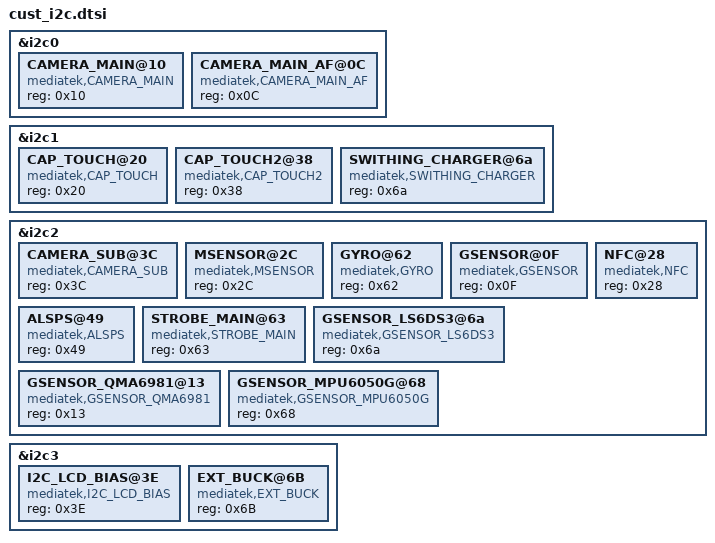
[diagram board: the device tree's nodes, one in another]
/*
 * Generated by MTK SP DrvGen Version 03.13.6 for MT6735M. Copyright MediaTek Inc. (C) 2013.
 * Tue Dec 06 09:41:16 2016
 * Do Not Modify the File.
 */

/*************************
 * I2C DTSI File
*************************/

&i2c0 {
	CAMERA_MAIN@10 {
		compatible = "mediatek,CAMERA_MAIN";
		reg = <0x10>;
	};

	CAMERA_MAIN_AF@0C {
		compatible = "mediatek,CAMERA_MAIN_AF";
		reg = <0x0C>;
	};

};

&i2c1 {
	CAP_TOUCH@20 {
		compatible = "mediatek,CAP_TOUCH";
		reg = <0x20>;
	};

	CAP_TOUCH2@38 {
		compatible = "mediatek,CAP_TOUCH2";
		reg = <0x38>;
	};

	SWITHING_CHARGER@6a {
		compatible = "mediatek,SWITHING_CHARGER";
		reg = <0x6a>;
	};

};

&i2c2 {
	CAMERA_SUB@3C {
		compatible = "mediatek,CAMERA_SUB";
		reg = <0x3C>;
	};

	MSENSOR@2C {
		compatible = "mediatek,MSENSOR";
		reg = <0x2C>;
	};

	GYRO@62 {
		compatible = "mediatek,GYRO";
		reg = <0x62>;
	};

	GSENSOR@0F {
		compatible = "mediatek,GSENSOR";
		reg = <0x0F>;
	};

	ALSPS@49 {
		compatible = "mediatek,ALSPS";
		reg = <0x49>;
	};

	NFC@28 {
		compatible = "mediatek,NFC";
		reg = <0x28>;
	};

	STROBE_MAIN@63 {
		compatible = "mediatek,STROBE_MAIN";
		reg = <0x63>;
	};

	GSENSOR_LS6DS3@6a {
		compatible = "mediatek,GSENSOR_LS6DS3";
		reg = <0x6a>;
	};

	GSENSOR_QMA6981@13 {
		compatible = "mediatek,GSENSOR_QMA6981";
		reg = <0x13>;
	};

	GSENSOR_MPU6050G@68 {
		compatible = "mediatek,GSENSOR_MPU6050G";
		reg = <0x68>;
	};

};

&i2c3 {
	I2C_LCD_BIAS@3E {
		compatible = "mediatek,I2C_LCD_BIAS";
		reg = <0x3E>;
	};

	EXT_BUCK@6B {
		compatible = "mediatek,EXT_BUCK";
		reg = <0x6B>;
	};

};

